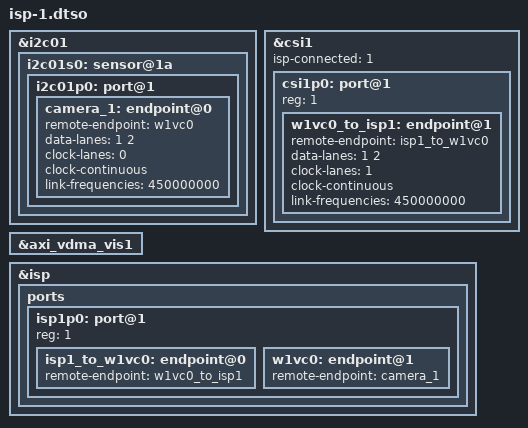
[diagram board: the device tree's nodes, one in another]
// SPDX-License-Identifier: (GPL-2.0+ OR MIT)
/*
 * Copyright (c) 2024 SiMa ai
 */

/dts-v1/;
/plugin/;

&i2c01 {
        i2c01s0: sensor@1a {
                i2c01p0: port@1 {
                        camera_1: endpoint@0 {
                                remote-endpoint = <&w1vc0>;
                                data-lanes = <1 2>;
                                clock-lanes = <0>;
                                clock-continuous;
                                link-frequencies = /bits/ 64 <450000000>;
                        };
                };
        };
};

&csi1 {
		status = "okay";
        isp-connected = <1>;
        csi1p0: port@1 {
                reg = <1>;
                w1vc0_to_isp1: endpoint@1 {
                        remote-endpoint = <&isp1_to_w1vc0>;
                        data-lanes = <1 2>;
                        clock-lanes = <1>;
                        clock-continuous;
                        link-frequencies = /bits/ 64 <450000000>;
                };
        };
};

&axi_vdma_vis1 {
        status = "okay";
};

&isp {
	status = "okay";
	ports {
		#address-cells = <1>;
		#size-cells = <0>;
        isp1p0: port@1 {
				reg = <1>;
                isp1_to_w1vc0: endpoint@0 {
                        remote-endpoint = <&w1vc0_to_isp1>;
                };
                w1vc0: endpoint@1 {
                        remote-endpoint = <&camera_1>;
                };
        };
	};
};
